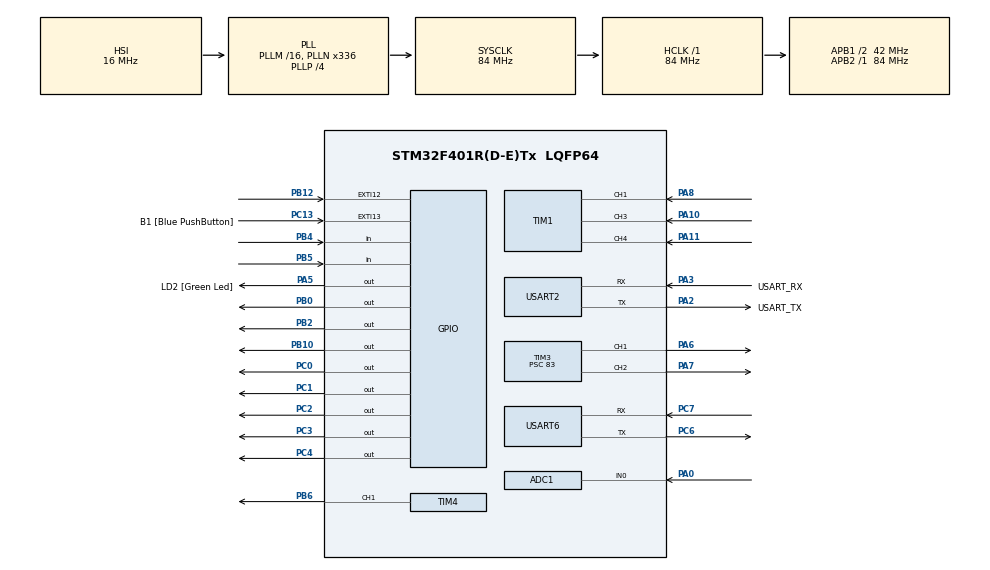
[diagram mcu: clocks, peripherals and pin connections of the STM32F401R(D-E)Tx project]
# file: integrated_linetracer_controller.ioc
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ADC1.Channel-0\#ChannelRegularConversion=ADC_CHANNEL_0
ADC1.NbrOfConversionFlag=1
ADC1.Rank-0\#ChannelRegularConversion=1
ADC1.SamplingTime-0\#ChannelRegularConversion=ADC_SAMPLETIME_3CYCLES
ADC1.master=1
Dma.Request0=USART6_RX
Dma.Request1=USART6_TX
Dma.USART6_RX.0.Direction=DMA_PERIPH_TO_MEMORY
Dma.USART6_RX.0.FIFOMode=DMA_FIFOMODE_DISABLE
Dma.USART6_RX.0.Instance=DMA2_Stream1
Dma.USART6_RX.0.MemDataAlignment=DMA_MDATAALIGN_BYTE
Dma.USART6_RX.0.MemInc=DMA_MINC_ENABLE
Dma.USART6_RX.0.Mode=DMA_CIRCULAR
Dma.USART6_RX.0.PeriphDataAlignment=DMA_PDATAALIGN_BYTE
Dma.USART6_RX.0.PeriphInc=DMA_PINC_DISABLE
Dma.USART6_RX.0.Priority=DMA_PRIORITY_HIGH
Dma.USART6_TX.1.Direction=DMA_MEMORY_TO_PERIPH
Dma.USART6_TX.1.FIFOMode=DMA_FIFOMODE_DISABLE
Dma.USART6_TX.1.Instance=DMA2_Stream6
Dma.USART6_TX.1.MemDataAlignment=DMA_MDATAALIGN_BYTE
Dma.USART6_TX.1.MemInc=DMA_MINC_ENABLE
Dma.USART6_TX.1.Mode=DMA_NORMAL
Dma.USART6_TX.1.PeriphDataAlignment=DMA_PDATAALIGN_BYTE
Dma.USART6_TX.1.PeriphInc=DMA_PINC_DISABLE
Dma.USART6_TX.1.Priority=DMA_PRIORITY_MEDIUM
FREERTOS.Tasks01=SensorTask,24,512,StartSensorTask,As weak,NULL,Dynamic,NULL,NULL;CommRxTask,32,512,StartCommRxTask,As weak,NULL,Dynamic,NULL,NULL;ControlTask,24,512,StartControlTask,As weak,NULL,Dynamic,NULL,NULL;SafetyTask,40,512,StartSafetyTask,As weak,NULL,Dynamic,NULL,NULL;CommTxTask,32,512,StartCommTxTask,As weak,NULL,Dynamic,NULL,NULL;HealthTask,16,512,StartHealthTask,As weak,NULL,Dynamic,NULL,NULL;UnloadTask,24,512,StartUnloadTask,As weak,NULL,Dynamic,NULL,NULL
FREERTOS.configMAX_TASK_NAME_LEN=24
Mcu.Family=STM32F4
Mcu.Name=STM32F401R(D-E)Tx
Mcu.Package=LQFP64
NVIC.DMA2_Stream1_IRQn=true\:5\:0\:false\:false\:true\:true\:false\:true\:true
NVIC.DMA2_Stream6_IRQn=true\:6\:0\:true\:false\:true\:true\:false\:true\:true
NVIC.EXTI15_10_IRQn=true\:5\:0\:false\:false\:true\:true\:true\:true\:true
NVIC.PriorityGroup=NVIC_PRIORITYGROUP_4
NVIC.TIM5_IRQn=true\:0\:0\:false\:false\:true\:false\:false\:true\:true
NVIC.TimeBase=TIM5_IRQn
NVIC.TimeBaseIP=TIM5
NVIC.USART6_IRQn=true\:5\:0\:false\:false\:true\:true\:true\:true\:true
PA0-WKUP.Signal=ADCx_IN0
PA10.Signal=S_TIM1_CH3
PA11.Signal=S_TIM1_CH4
PA13.GPIO_Label=TMS
PA13.Mode=Trace_Asynchronous_SW
PA13.Signal=SYS_JTMS-SWDIO
PA14.GPIO_Label=TCK
PA14.Mode=Trace_Asynchronous_SW
PA14.Signal=SYS_JTCK-SWCLK
PA2.GPIO_Label=USART_TX
PA2.GPIO_Mode=GPIO_MODE_AF_PP
PA2.GPIO_PuPd=GPIO_NOPULL
PA2.GPIO_Speed=GPIO_SPEED_FREQ_LOW
PA2.Mode=Asynchronous
PA2.Signal=USART2_TX
PA3.GPIO_Label=USART_RX
PA3.GPIO_Mode=GPIO_MODE_AF_PP
PA3.GPIO_PuPd=GPIO_NOPULL
PA3.GPIO_Speed=GPIO_SPEED_FREQ_LOW
PA3.Mode=Asynchronous
PA3.Signal=USART2_RX
PA5.GPIO_Label=LD2 [Green Led]
PA5.GPIO_Mode=GPIO_MODE_OUTPUT_PP
PA5.GPIO_PuPd=GPIO_NOPULL
PA5.GPIO_Speed=GPIO_SPEED_FREQ_LOW
PA5.Signal=GPIO_Output
PA6.Signal=S_TIM3_CH1
PA7.Signal=S_TIM3_CH2
PA8.Signal=S_TIM1_CH1
PB0.Signal=GPIO_Output
PB10.Signal=GPIO_Output
PB12.GPIO_ModeDefaultEXTI=GPIO_MODE_IT_FALLING
PB12.GPIO_PuPd=GPIO_PULLUP
PB12.Signal=GPXTI12
PB2.Signal=GPIO_Output
PB3.GPIO_Label=SWO
PB3.Mode=Trace_Asynchronous_SW
PB3.Signal=SYS_JTDO-SWO
PB4.Signal=GPIO_Input
PB5.Signal=GPIO_Input
PB6.Signal=S_TIM4_CH1
PC0.Signal=GPIO_Output
PC1.Signal=GPIO_Output
PC13-ANTI_TAMP.GPIO_Label=B1 [Blue PushButton]
PC13-ANTI_TAMP.GPIO_ModeDefaultEXTI=GPIO_MODE_IT_FALLING
PC13-ANTI_TAMP.GPIO_PuPd=GPIO_NOPULL
PC13-ANTI_TAMP.Signal=GPXTI13
PC14-OSC32_IN.Mode=LSE-External-Oscillator
PC14-OSC32_IN.Signal=RCC_OSC32_IN
PC15-OSC32_OUT.Mode=LSE-External-Oscillator
PC15-OSC32_OUT.Signal=RCC_OSC32_OUT
PC2.Signal=GPIO_Output
PC3.Signal=GPIO_Output
PC4.Signal=GPIO_Output
PC6.Mode=Asynchronous
PC6.Signal=USART6_TX
PC7.Mode=Asynchronous
PC7.Signal=USART6_RX
PH0\ -\ OSC_IN.Mode=HSE-External-Clock-Source
PH0\ -\ OSC_IN.Signal=RCC_OSC_IN
PH1\ -\ OSC_OUT.Mode=HSE-External-Clock-Source
PH1\ -\ OSC_OUT.Signal=RCC_OSC_OUT
ProjectManager.HeapSize=0x200
ProjectManager.StackSize=0x400
ProjectManager.TargetToolchain=STM32CubeIDE
RCC.48MHZClocksFreq_Value=48000000
RCC.AHBFreq_Value=84000000
RCC.APB1CLKDivider=RCC_HCLK_DIV2
RCC.APB1Freq_Value=42000000
RCC.APB1TimFreq_Value=84000000
RCC.APB2Freq_Value=84000000
RCC.APB2TimFreq_Value=84000000
RCC.CortexFreq_Value=84000000
RCC.HCLKFreq_Value=84000000
RCC.HSE_VALUE=8000000
RCC.HSI_VALUE=16000000
RCC.PLLN=336
RCC.PLLP=RCC_PLLP_DIV4
RCC.PLLQ=7
RCC.SYSCLKFreq_VALUE=84000000
RCC.SYSCLKSource=RCC_SYSCLKSOURCE_PLLCLK
RCC.VCOOutputFreq_Value=336000000
SH.ADCx_IN0.0=ADC1_IN0,IN0
SH.S_TIM1_CH1.0=TIM1_CH1,Input_Capture1_from_TI1
SH.S_TIM1_CH3.0=TIM1_CH3,Input_Capture3_from_TI3
SH.S_TIM1_CH4.0=TIM1_CH4,Input_Capture4_from_TI4
SH.S_TIM3_CH1.0=TIM3_CH1,PWM Generation1 CH1
SH.S_TIM3_CH2.0=TIM3_CH2,PWM Generation2 CH2
SH.S_TIM4_CH1.0=TIM4_CH1,PWM Generation1 CH1
TIM1.Channel-Input_Capture1_from_TI1=TIM_CHANNEL_1
TIM1.Channel-Input_Capture3_from_TI3=TIM_CHANNEL_3
TIM1.Channel-Input_Capture4_from_TI4=TIM_CHANNEL_4
TIM3.AutoReloadPreload=TIM_AUTORELOAD_PRELOAD_ENABLE
TIM3.Channel-PWM\ Generation1\ CH1=TIM_CHANNEL_1
TIM3.Channel-PWM\ Generation2\ CH2=TIM_CHANNEL_2
TIM3.Period=999
TIM3.Prescaler=83
TIM4.AutoReloadPreload=TIM_AUTORELOAD_PRELOAD_ENABLE
TIM4.Channel-PWM\ Generation1\ CH1=TIM_CHANNEL_1
TIM4.Period=19999
TIM4.Prescaler=83
USART2.VirtualMode=VM_ASYNC
USART6.VirtualMode=VM_ASYNC
VP_FREERTOS_VS_CMSIS_V2.Mode=CMSIS_V2
VP_SYS_VS_tim5.Mode=TIM5
VP_TIM1_VS_ClockSourceINT.Mode=Internal
VP_TIM3_VS_ClockSourceINT.Mode=Internal
VP_TIM4_VS_ClockSourceINT.Mode=Internal
board=NUCLEO-F401RE

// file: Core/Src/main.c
/* USER CODE BEGIN Header */
/**
  ******************************************************************************
  * @file           : main.c
  * @brief          : Main program body
  ******************************************************************************
  * @attention
  *
  * Copyright (c) 2026 STMicroelectronics.
  * All rights reserved.
  *
  * This software is licensed under terms that can be found in the LICENSE file
  * in the root directory of this software component.
  * If no LICENSE file comes with this software, it is provided AS-IS.
  *
  ******************************************************************************
  */
/* USER CODE END Header */
#include "main.h"
#include "cmsis_os.h"
#include "adc.h"
#include "dma.h"
#include "tim.h"
#include "usart.h"
#include "gpio.h"

void SystemClock_Config(void);
void MX_FREERTOS_Init(void);

int main(void)
{

  /* MCU Configuration--------------------------------------------------------*/

  /* Reset of all peripherals, Initializes the Flash interface and the Systick. */
  HAL_Init();

  /* Configure the system clock */
  SystemClock_Config();

  /* Initialize all configured peripherals */
  MX_GPIO_Init();
  MX_DMA_Init();
  MX_USART2_UART_Init();
  MX_USART6_UART_Init();
  MX_ADC1_Init();
  MX_TIM1_Init();
  MX_TIM3_Init();
  MX_TIM4_Init();

  /* Init scheduler */
  osKernelInitialize();  /* Call init function for freertos objects (in cmsis_os2.c) */
  MX_FREERTOS_Init();

  /* Start scheduler */
  osKernelStart();

  /* We should never get here as control is now taken by the scheduler */

  /* Infinite loop */
  while (1)
  {

  }
}

void SystemClock_Config(void)
{
  RCC_OscInitTypeDef RCC_OscInitStruct = {0};
  RCC_ClkInitTypeDef RCC_ClkInitStruct = {0};

  /** Configure the main internal regulator output voltage
  */
  __HAL_RCC_PWR_CLK_ENABLE();
  __HAL_PWR_VOLTAGESCALING_CONFIG(PWR_REGULATOR_VOLTAGE_SCALE2);

  /** Initializes the RCC Oscillators according to the specified parameters
  * in the RCC_OscInitTypeDef structure.
  */
  RCC_OscInitStruct.OscillatorType = RCC_OSCILLATORTYPE_HSI;
  RCC_OscInitStruct.HSIState = RCC_HSI_ON;
  RCC_OscInitStruct.HSICalibrationValue = RCC_HSICALIBRATION_DEFAULT;
  RCC_OscInitStruct.PLL.PLLState = RCC_PLL_ON;
  RCC_OscInitStruct.PLL.PLLSource = RCC_PLLSOURCE_HSI;
  RCC_OscInitStruct.PLL.PLLM = 16;
  RCC_OscInitStruct.PLL.PLLN = 336;
  RCC_OscInitStruct.PLL.PLLP = RCC_PLLP_DIV4;
  RCC_OscInitStruct.PLL.PLLQ = 7;
  if (HAL_RCC_OscConfig(&RCC_OscInitStruct) != HAL_OK)
  {
    Error_Handler();
  }

  /** Initializes the CPU, AHB and APB buses clocks
  */
  RCC_ClkInitStruct.ClockType = RCC_CLOCKTYPE_HCLK|RCC_CLOCKTYPE_SYSCLK
                              |RCC_CLOCKTYPE_PCLK1|RCC_CLOCKTYPE_PCLK2;
  RCC_ClkInitStruct.SYSCLKSource = RCC_SYSCLKSOURCE_PLLCLK;
  RCC_ClkInitStruct.AHBCLKDivider = RCC_SYSCLK_DIV1;
  RCC_ClkInitStruct.APB1CLKDivider = RCC_HCLK_DIV2;
  RCC_ClkInitStruct.APB2CLKDivider = RCC_HCLK_DIV1;

  if (HAL_RCC_ClockConfig(&RCC_ClkInitStruct, FLASH_LATENCY_2) != HAL_OK)
  {
    Error_Handler();
  }
}

void HAL_TIM_PeriodElapsedCallback(TIM_HandleTypeDef *htim)
{
  if (htim->Instance == TIM5)
  {
    HAL_IncTick();
  }
}

void Error_Handler(void)
{
  __disable_irq();
  while (1)
  {
  }
}

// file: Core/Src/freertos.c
/* USER CODE BEGIN Header */
/**
  ******************************************************************************
  * File Name          : freertos.c
  * Description        : Code for freertos applications
  ******************************************************************************
  * @attention
  *
  * Copyright (c) 2026 STMicroelectronics.
  * All rights reserved.
  *
  * This software is licensed under terms that can be found in the LICENSE file
  * in the root directory of this software component.
  * If no LICENSE file comes with this software, it is provided AS-IS.
  *
  ******************************************************************************
  */
/* USER CODE END Header */

#include "FreeRTOS.h"
#include "task.h"
#include "main.h"
#include "cmsis_os.h"

/* USER CODE BEGIN Includes */
#include "app_queues.h"

/* USER CODE END Includes */

/* Definitions for SensorTask */
osThreadId_t SensorTaskHandle;
const osThreadAttr_t SensorTask_attributes = {
  .name = "SensorTask",
  .stack_size = 512 * 4,
  .priority = (osPriority_t) osPriorityNormal,
};
/* Definitions for CommRxTask */
osThreadId_t CommRxTaskHandle;
const osThreadAttr_t CommRxTask_attributes = {
  .name = "CommRxTask",
  .stack_size = 512 * 4,
  .priority = (osPriority_t) osPriorityAboveNormal,
};
/* Definitions for ControlTask */
osThreadId_t ControlTaskHandle;
const osThreadAttr_t ControlTask_attributes = {
  .name = "ControlTask",
  .stack_size = 512 * 4,
  .priority = (osPriority_t) osPriorityNormal,
};
/* Definitions for SafetyTask */
osThreadId_t SafetyTaskHandle;
const osThreadAttr_t SafetyTask_attributes = {
  .name = "SafetyTask",
  .stack_size = 512 * 4,
  .priority = (osPriority_t) osPriorityHigh,
};
/* Definitions for CommTxTask */
osThreadId_t CommTxTaskHandle;
const osThreadAttr_t CommTxTask_attributes = {
  .name = "CommTxTask",
  .stack_size = 512 * 4,
  .priority = (osPriority_t) osPriorityAboveNormal,
};
/* Definitions for HealthTask */
osThreadId_t HealthTaskHandle;
const osThreadAttr_t HealthTask_attributes = {
  .name = "HealthTask",
  .stack_size = 512 * 4,
  .priority = (osPriority_t) osPriorityBelowNormal,
};
/* Definitions for UnloadTask */
osThreadId_t UnloadTaskHandle;
const osThreadAttr_t UnloadTask_attributes = {
  .name = "UnloadTask",
  .stack_size = 512 * 4,
  .priority = (osPriority_t) osPriorityNormal,
};

void StartSensorTask(void *argument);
void StartCommRxTask(void *argument);
void StartControlTask(void *argument);
void StartSafetyTask(void *argument);
void StartCommTxTask(void *argument);
void StartHealthTask(void *argument);
void StartUnloadTask(void *argument);

void MX_FREERTOS_Init(void); /* (MISRA C 2004 rule 8.1) */

void MX_FREERTOS_Init(void) {

  /* USER CODE BEGIN RTOS_QUEUES */
  if (AppQueues_Init() == 0U)
  {
    Error_Handler();
  }
  /* USER CODE END RTOS_QUEUES */

  /* Create the thread(s) */
  /* creation of SensorTask */
  SensorTaskHandle = osThreadNew(StartSensorTask, NULL, &SensorTask_attributes);

  /* creation of CommRxTask */
  CommRxTaskHandle = osThreadNew(StartCommRxTask, NULL, &CommRxTask_attributes);

  /* creation of ControlTask */
  ControlTaskHandle = osThreadNew(StartControlTask, NULL, &ControlTask_attributes);

  /* creation of SafetyTask */
  SafetyTaskHandle = osThreadNew(StartSafetyTask, NULL, &SafetyTask_attributes);

  /* creation of CommTxTask */
  CommTxTaskHandle = osThreadNew(StartCommTxTask, NULL, &CommTxTask_attributes);

  /* creation of HealthTask */
  HealthTaskHandle = osThreadNew(StartHealthTask, NULL, &HealthTask_attributes);

  /* creation of UnloadTask */
  UnloadTaskHandle = osThreadNew(StartUnloadTask, NULL, &UnloadTask_attributes);

}

__weak void StartSensorTask(void *argument)
{
  for(;;)
  {
    osDelay(1);
  }
}

__weak void StartCommRxTask(void *argument)
{
  for(;;)
  {
    osDelay(1);
  }
}

__weak void StartControlTask(void *argument)
{
  for(;;)
  {
    osDelay(1);
  }
}

__weak void StartSafetyTask(void *argument)
{
  for(;;)
  {
    osDelay(1);
  }
}

__weak void StartCommTxTask(void *argument)
{
  for(;;)
  {
    osDelay(1);
  }
}

__weak void StartHealthTask(void *argument)
{
  for(;;)
  {
    osDelay(1);
  }
}

__weak void StartUnloadTask(void *argument)
{
  for(;;)
  {
    osDelay(1);
  }
}
